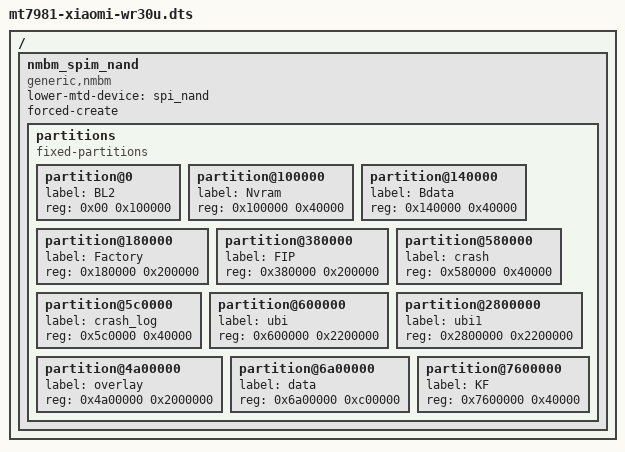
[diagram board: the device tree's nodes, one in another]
/dts-v1/;
#include "mt7981-xiaomi-wr30u-base.dtsi"

/ {
        nmbm_spim_nand {
                compatible = "generic,nmbm";
                #address-cells = <1>;
                #size-cells = <1>;

                lower-mtd-device = <&spi_nand>;
                forced-create;

                partitions {
                        compatible = "fixed-partitions";
                        #address-cells = <0x01>;
                        #size-cells = <0x01>;

                        partition@0 {
                                label = "BL2";
                                reg = <0x00 0x100000>;
                        };

                        partition@100000 {
                                label = "Nvram";
                                reg = <0x100000 0x40000>;
                        };

                        partition@140000 {
                                label = "Bdata";
                                reg = <0x140000 0x40000>;
                        };

                        partition@180000 {
                                label = "Factory";
                                reg = <0x180000 0x200000>;
                        };

                        partition@380000 {
                                label = "FIP";
                                reg = <0x380000 0x200000>;
                        };

                        partition@580000 {
                                label = "crash";
                                reg = <0x580000 0x40000>;
                        };

                        partition@5c0000 {
                                label = "crash_log";
                                reg = <0x5c0000 0x40000>;
                        };

                        partition@600000 {
                                label = "ubi";
                                reg = <0x600000 0x2200000>;
                        };

                        partition@2800000 {
                                label = "ubi1";
                                reg = <0x2800000 0x2200000>;
                        };

                        partition@4a00000 {
                                label = "overlay";
                                reg = <0x4a00000 0x2000000>;
                        };

                        partition@6a00000 {
                                label = "data";
                                reg = <0x6a00000 0xc00000>;
                        };

                        partition@7600000 {
                                label = "KF";
                                reg = <0x7600000 0x40000>;
                        };
                };
        };
};
